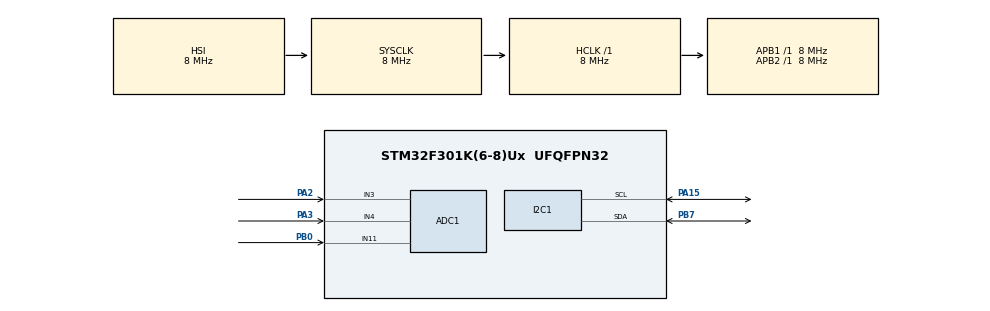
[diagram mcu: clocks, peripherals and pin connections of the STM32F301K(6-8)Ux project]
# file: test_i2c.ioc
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ADC1.Channel-0\#ChannelRegularConversion=ADC_CHANNEL_3
ADC1.Channel-1\#ChannelRegularConversion=ADC_CHANNEL_4
ADC1.Channel-2\#ChannelRegularConversion=ADC_CHANNEL_11
ADC1.ClockPrescaler=ADC_CLOCK_SYNC_PCLK_DIV1
ADC1.ContinuousConvMode=ENABLE
ADC1.DMAContinuousRequests=ENABLE
ADC1.EOCSelection=ADC_EOC_SEQ_CONV
ADC1.EnableInjectedConversion=DISABLE
ADC1.NbrOfConversion=3
ADC1.NbrOfConversionFlag=1
ADC1.Offset-0\#ChannelRegularConversion=0
ADC1.Offset-1\#ChannelRegularConversion=0
ADC1.Offset-2\#ChannelRegularConversion=0
ADC1.OffsetNumber-0\#ChannelRegularConversion=ADC_OFFSET_NONE
ADC1.OffsetNumber-1\#ChannelRegularConversion=ADC_OFFSET_NONE
ADC1.OffsetNumber-2\#ChannelRegularConversion=ADC_OFFSET_NONE
ADC1.Overrun=ADC_OVR_DATA_PRESERVED
ADC1.Rank-0\#ChannelRegularConversion=1
ADC1.Rank-1\#ChannelRegularConversion=2
ADC1.Rank-2\#ChannelRegularConversion=3
ADC1.SamplingTime-0\#ChannelRegularConversion=ADC_SAMPLETIME_61CYCLES_5
ADC1.SamplingTime-1\#ChannelRegularConversion=ADC_SAMPLETIME_61CYCLES_5
ADC1.SamplingTime-2\#ChannelRegularConversion=ADC_SAMPLETIME_61CYCLES_5
ADC1.master=1
Dma.ADC1.0.Direction=DMA_PERIPH_TO_MEMORY
Dma.ADC1.0.Instance=DMA1_Channel1
Dma.ADC1.0.MemDataAlignment=DMA_MDATAALIGN_HALFWORD
Dma.ADC1.0.MemInc=DMA_MINC_ENABLE
Dma.ADC1.0.Mode=DMA_NORMAL
Dma.ADC1.0.PeriphDataAlignment=DMA_PDATAALIGN_HALFWORD
Dma.ADC1.0.PeriphInc=DMA_PINC_DISABLE
Dma.ADC1.0.Priority=DMA_PRIORITY_LOW
Dma.Request0=ADC1
I2C1.I2C_Fall_Time=200
I2C1.I2C_Rise_Time=200
I2C1.OwnAddress=0x78
I2C1.Timing=0x00301D29
Mcu.Family=STM32F3
Mcu.Name=STM32F301K(6-8)Ux
Mcu.Package=UFQFPN32
NVIC.ADC1_IRQn=true\:0\:0\:false\:false\:true\:true\:true
NVIC.DMA1_Channel1_IRQn=true\:0\:0\:false\:false\:true\:false\:true
NVIC.PriorityGroup=NVIC_PRIORITYGROUP_4
PA15.Mode=I2C
PA15.Signal=I2C1_SCL
PA2.Mode=IN3-Single-Ended
PA2.Signal=ADC1_IN3
PA3.Mode=IN4-Single-Ended
PA3.Signal=ADC1_IN4
PB0.Mode=IN11-Single-Ended
PB0.Signal=ADC1_IN11
PB7.Mode=I2C
PB7.Signal=I2C1_SDA
ProjectManager.HeapSize=0x200
ProjectManager.StackSize=0x400
ProjectManager.TargetToolchain=STM32CubeIDE
RCC.AHBFreq_Value=8000000
RCC.APB1Freq_Value=8000000
RCC.APB2Freq_Value=8000000
RCC.CortexFreq_Value=8000000
RCC.HSE_VALUE=8000000
RCC.HSI_VALUE=8000000
RCC.PLLMUL=RCC_PLL_MUL4
RCC.SYSCLKFreq_VALUE=8000000
board=custom

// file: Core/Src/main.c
/* USER CODE BEGIN Header */
/**
  ******************************************************************************
  * @file           : main.c
  * @brief          : Main program body
  ******************************************************************************
  * @attention
  *
  * <h2><center>&copy; Copyright (c) 2019 STMicroelectronics.
  * All rights reserved.</center></h2>
  *
  * This software component is licensed by ST under BSD 3-Clause license,
  * the "License"; You may not use this file except in compliance with the
  * License. You may obtain a copy of the License at:
  *                        opensource.org/licenses/BSD-3-Clause
  *
  ******************************************************************************
  */
/* USER CODE END Header */

#include "main.h"
#include "adc.h"
#include "dma.h"
#include "i2c.h"
#include "gpio.h"

void SystemClock_Config(void);

/* USER CODE BEGIN 0 */
uint8_t aTxBuffer[20] = {1, 2, 3, 4, 5, 6, 7, 8, 9, 10, 11, 12, 13, 14, 15, 16, 17, 18, 19, 20};
/* USER CODE END 0 */

int main(void)
{

  /* MCU Configuration--------------------------------------------------------*/

  /* Reset of all peripherals, Initializes the Flash interface and the Systick. */
  HAL_Init();

  /* Configure the system clock */
  SystemClock_Config();

  /* Initialize all configured peripherals */
  MX_GPIO_Init();
  MX_I2C1_Init();
  MX_ADC1_Init();
  MX_DMA_Init();
  /* USER CODE BEGIN 2 */

  // DMA error correction since above, DMA fails at linking to ADC because
  HAL_ADC_MspDeInit(&hadc1);
  HAL_ADC_MspInit(&hadc1);
//  cameraDetectionTask();
  /* USER CODE END 2 */

  /* Infinite loop */
  /* USER CODE BEGIN WHILE */
  while (1)
  {
	  if(HAL_I2C_Slave_Transmit(&hi2c1, (uint8_t*)aTxBuffer, sizeof(aTxBuffer), 10000)!= HAL_OK)
	  {
	    /* Transfer error in transmission process */
	    Error_Handler();
	  }
	  HAL_Delay(1000);
    /* USER CODE END WHILE */

  }
}

void SystemClock_Config(void)
{
  RCC_OscInitTypeDef RCC_OscInitStruct = {0};
  RCC_ClkInitTypeDef RCC_ClkInitStruct = {0};
  RCC_PeriphCLKInitTypeDef PeriphClkInit = {0};

  /** Initializes the CPU, AHB and APB busses clocks
  */
  RCC_OscInitStruct.OscillatorType = RCC_OSCILLATORTYPE_HSI;
  RCC_OscInitStruct.HSIState = RCC_HSI_ON;
  RCC_OscInitStruct.HSICalibrationValue = RCC_HSICALIBRATION_DEFAULT;
  RCC_OscInitStruct.PLL.PLLState = RCC_PLL_NONE;
  if (HAL_RCC_OscConfig(&RCC_OscInitStruct) != HAL_OK)
  {
    Error_Handler();
  }
  /** Initializes the CPU, AHB and APB busses clocks
  */
  RCC_ClkInitStruct.ClockType = RCC_CLOCKTYPE_HCLK|RCC_CLOCKTYPE_SYSCLK
                              |RCC_CLOCKTYPE_PCLK1|RCC_CLOCKTYPE_PCLK2;
  RCC_ClkInitStruct.SYSCLKSource = RCC_SYSCLKSOURCE_HSI;
  RCC_ClkInitStruct.AHBCLKDivider = RCC_SYSCLK_DIV1;
  RCC_ClkInitStruct.APB1CLKDivider = RCC_HCLK_DIV1;
  RCC_ClkInitStruct.APB2CLKDivider = RCC_HCLK_DIV1;

  if (HAL_RCC_ClockConfig(&RCC_ClkInitStruct, FLASH_LATENCY_0) != HAL_OK)
  {
    Error_Handler();
  }
  PeriphClkInit.PeriphClockSelection = RCC_PERIPHCLK_I2C1;
  PeriphClkInit.I2c1ClockSelection = RCC_I2C1CLKSOURCE_HSI;
  if (HAL_RCCEx_PeriphCLKConfig(&PeriphClkInit) != HAL_OK)
  {
    Error_Handler();
  }
}

void Error_Handler(void)
{
}

/************************ (C) COPYRIGHT STMicroelectronics *****END OF FILE****/
